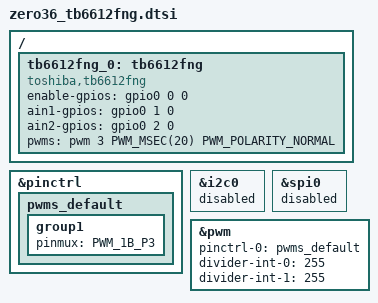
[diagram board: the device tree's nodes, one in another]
/*
 * Copyright (c) 2020 Pete Johanson
 *
 * SPDX-License-Identifier: MIT
 */

#include <dt-bindings/pinctrl/rpi-pico-rp2040-pinctrl.h>
#include <zephyr/dt-bindings/pwm/pwm.h>

&pinctrl {
    pwms_default: pwms_default {
        group1 {
            pinmux = <PWM_1B_P3>;
        };
        // group2 {
        //     pinmux = <PWM_2A_P4>;
        // };
    };
};

&i2c0 {
	status = "disabled";
};

&spi0 {
	status = "disabled";
};

&pwm {
    status = "okay";
    pinctrl-0 = <&pwms_default>;
    pinctrl-names = "default";
    divider-int-0 = <255>;
    divider-int-1 = <255>;
};

/ {
  tb6612fng_0: tb6612fng {
    compatible = "toshiba,tb6612fng";

    enable-gpios = <&gpio0 0 0 (GPIO_ACTIVE_HIGH | GPIO_PULL_DOWN)>;
    
    ain1-gpios = <&gpio0 1 0 (GPIO_ACTIVE_HIGH | GPIO_PULL_DOWN)>;
    ain2-gpios = <&gpio0 2 0 (GPIO_ACTIVE_HIGH | GPIO_PULL_DOWN)>;

    // bin1-gpios = <&gpio0 5 0 (GPIO_ACTIVE_HIGH | GPIO_PULL_DOWN)>;
    // bin2-gpios = <&gpio0 5 0 (GPIO_ACTIVE_HIGH | GPIO_PULL_DOWN)>;

    pwms = <&pwm 3 PWM_MSEC(20) PWM_POLARITY_NORMAL>
         //, <&pwm 4 PWM_MSEC(20) PWM_POLARITY_NORMAL>
         ;
  };
};
